# STM32F100RCT6 register map
File version: 1.0
Registers are 32-bit, access not given, reset 0x0 unless marked. A register's access mark holds for its fields unless they carry their own. Offsets are from the block's base; [hi:lo] are bit positions; {n}, {i} and the like mark numbered series; 'fields as' and 'values as' point back to an identical list.

## CEC
Base 0x40007800
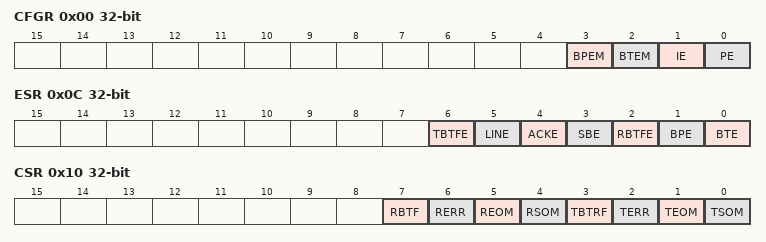
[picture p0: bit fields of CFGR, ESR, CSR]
0x00 CFGR
  [3] BPEM, [2] BTEM, [1] IE, [0] PE
0x04 OAR
  [3:0] OAR
0x08 PRE
  [13:0] PRESC
0x0C ESR
  [6] TBTFE, [5] LINE, [4] ACKE, [3] SBE, [2] RBTFE, [1] BPE, [0] BTE
0x10 CSR
  [7] RBTF, [6] RERR, [5] REOM, [4] RSOM, [3] TBTRF, [2] TERR, [1] TEOM, [0] TSOM
0x14 TXD
  [7:0] TXD
0x18 RXD
  [7:0] RXD

## AFIO
Base 0x40010000
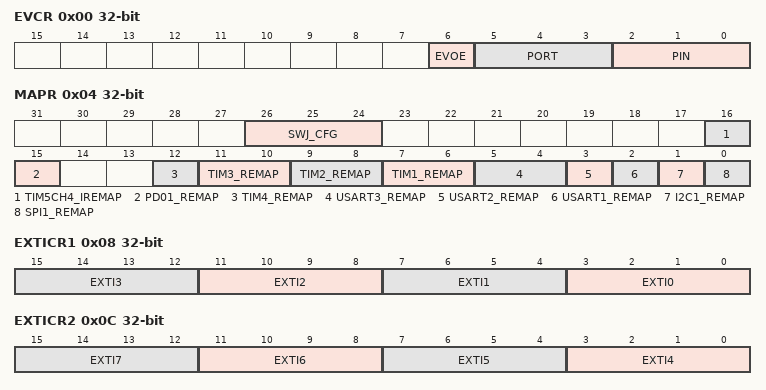
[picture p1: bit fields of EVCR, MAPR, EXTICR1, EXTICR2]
0x00 EVCR
  [6] EVOE, [5:3] PORT, [2:0] PIN
0x04 MAPR
  [26:24] SWJ_CFG, [16] TIM5CH4_IREMAP, [15] PD01_REMAP, [12] TIM4_REMAP, [11:10] TIM3_REMAP, [9:8] TIM2_REMAP, [7:6] TIM1_REMAP, [5:4] USART3_REMAP, [3] USART2_REMAP, [2] USART1_REMAP, [1] I2C1_REMAP, [0] SPI1_REMAP
0x08 EXTICR1
  [4n+3:4n] EXTI{n} (n=0..3)
0x0C EXTICR2
  [4n-13:4n-16] EXTI{n} (n=4..7)
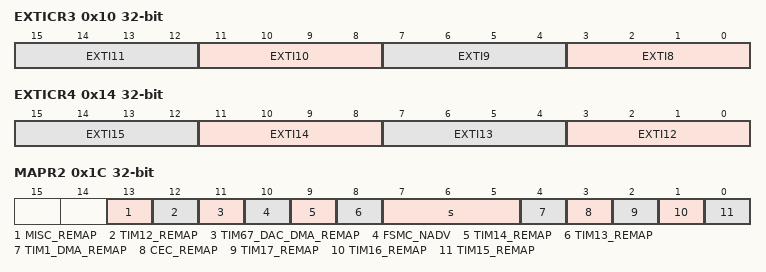
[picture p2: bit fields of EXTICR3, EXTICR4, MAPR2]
0x10 EXTICR3
  [4n-29:4n-32] EXTI{n} (n=8..11)
0x14 EXTICR4
  [4n-45:4n-48] EXTI{n} (n=12..15)
0x1C MAPR2
  [13] MISC_REMAP, [12] TIM12_REMAP, [11] TIM67_DAC_DMA_REMAP, [10] FSMC_NADV, [9] TIM14_REMAP, [8] TIM13_REMAP, [7:5] s, [4] TIM1_DMA_REMAP, [3] CEC_REMAP, [2] TIM17_REMAP, [1] TIM16_REMAP, [0] TIM15_REMAP

## EXTI
Base 0x40010400
0x00 IMR
0x04 EMR
0x08 RTSR
0x0C FTSR
0x10 SWIER
0x14 PR

## GPIOA
Base 0x40010800
Same registers: GPIOB 0x40010C00, GPIOC 0x40011000, GPIOD 0x40011400, GPIOE 0x40011800, GPIOF 0x40011C00, GPIOG 0x40012000
0x00 CRL
0x04 CRH
0x08 IDR
0x0C ODR
0x10 BSRR
0x14 BRR
0x18 LCKR

## ADC1
Base 0x40012400
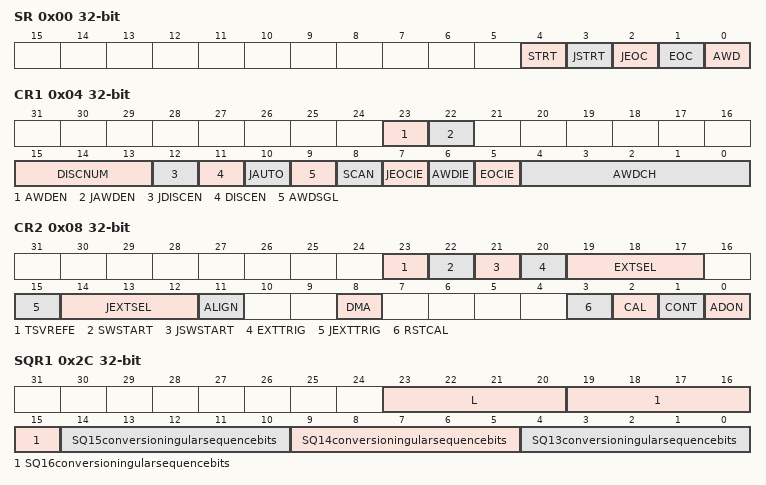
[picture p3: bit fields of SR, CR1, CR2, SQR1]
0x00 SR
  [4] STRT, [3] JSTRT, [2] JEOC, [1] EOC, [0] AWD
0x04 CR1
  [23] AWDEN, [22] JAWDEN, [15:13] DISCNUM, [12] JDISCEN, [11] DISCEN, [10] JAUTO, [9] AWDSGL, [8] SCAN, [7] JEOCIE, [6] AWDIE, [5] EOCIE, [4:0] AWDCH
0x08 CR2
  [23] TSVREFE, [22] SWSTART, [21] JSWSTART, [20] EXTTRIG, [19:17] EXTSEL, [15] JEXTTRIG, [14:12] JEXTSEL, [11] ALIGN, [8] DMA, [3] RSTCAL, [2] CAL, [1] CONT, [0] ADON
0x0C SMPR1
  [31:0] SMP
0x10 SMPR2
  [31:0] SMP
{0x10+4i} JOFR{i} (i=1..4)
  [11:0] JOFFSET{i}
0x24 HTR
  [11:0] HT
0x28 LTR
  [11:0] LT
0x2C SQR1
  [23:20] L, [5n-61:5n-65] SQ{n}conversioningularsequencebits (n=13..16)
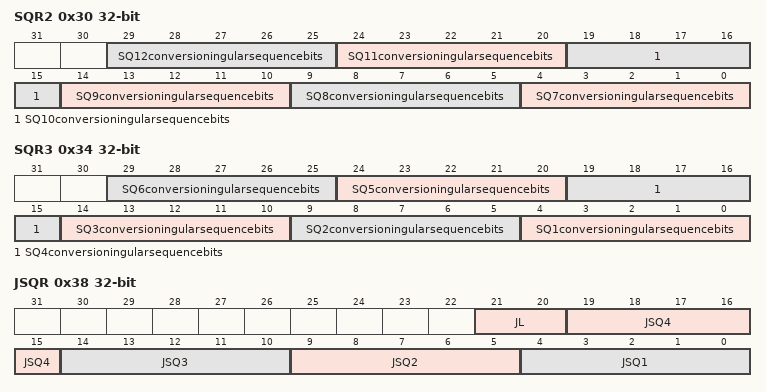
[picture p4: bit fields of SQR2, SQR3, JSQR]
0x30 SQR2
  [5n-31:5n-35] SQ{n}conversioningularsequencebits (n=7..12)
0x34 SQR3
  [5n-1:5n-5] SQ{n}conversioningularsequencebits (n=1..6)
0x38 JSQR
  [21:20] JL, [5n-1:5n-5] JSQ{n} (n=1..4)
{0x38+4i} JDR{i} (i=1..4)
  [15:0] JDATA
0x4C DR
  [15:0] gularDATA

## TIM15
Base 0x40014000
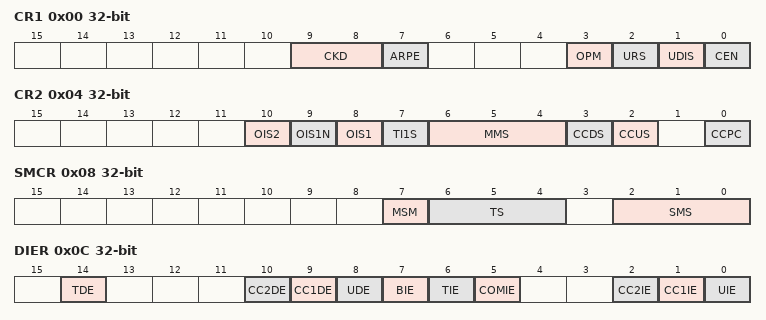
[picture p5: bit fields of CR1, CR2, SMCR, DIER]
0x00 CR1
  [9:8] CKD, [7] ARPE, [3] OPM, [2] URS, [1] UDIS, [0] CEN
0x04 CR2
  [10] OIS2, [9] OIS1N, [8] OIS1, [7] TI1S, [6:4] MMS, [3] CCDS, [2] CCUS, [0] CCPC
0x08 SMCR
  [7] MSM, [6:4] TS, [2:0] SMS
0x0C DIER
  [14] TDE, [10] CC2DE, [9] CC1DE, [8] UDE, [7] BIE, [6] TIE, [5] COMIE, [2] CC2IE, [1] CC1IE, [0] UIE
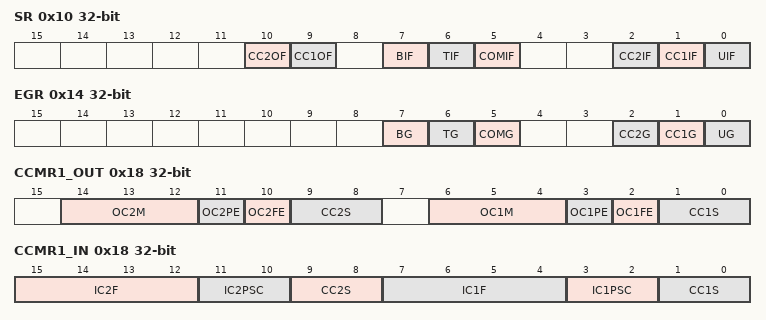
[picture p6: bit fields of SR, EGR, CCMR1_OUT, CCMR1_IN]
0x10 SR
  [10] CC2OF, [9] CC1OF, [7] BIF, [6] TIF, [5] COMIF, [2] CC2IF, [1] CC1IF, [0] UIF
0x14 EGR
  [7] BG, [6] TG, [5] COMG, [2] CC2G, [1] CC1G, [0] UG
0x18 CCMR1_OUT
  [14:12] OC2M, [11] OC2PE, [10] OC2FE, [9:8] CC2S, [6:4] OC1M, [3] OC1PE, [2] OC1FE, [1:0] CC1S
0x18 CCMR1_IN
  [15:12] IC2F, [11:10] IC2PSC, [9:8] CC2S, [7:4] IC1F, [3:2] IC1PSC, [1:0] CC1S
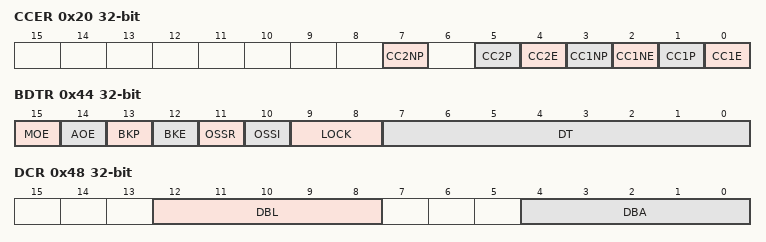
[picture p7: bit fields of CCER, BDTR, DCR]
0x20 CCER
  [7] CC2NP, [5] CC2P, [4] CC2E, [3] CC1NP, [2] CC1NE, [1] CC1P, [0] CC1E
0x24 CNT
  [15:0] CNT
0x28 PSC
  [15:0] PSC
0x2C ARR
  [15:0] ARR
0x30 RCR
  [7:0] REP
0x34 CCR1
  [15:0] CCR1
0x38 CCR2
  [15:0] CCR2
0x44 BDTR
  [15] MOE, [14] AOE, [13] BKP, [12] BKE, [11] OSSR, [10] OSSI, [9:8] LOCK, [7:0] DT
0x48 DCR
  [12:8] DBL, [4:0] DBA
0x4C DMAR
  [15:0] DMAB

## TIM16
Base 0x40014400
Same registers: TIM17 0x40014800
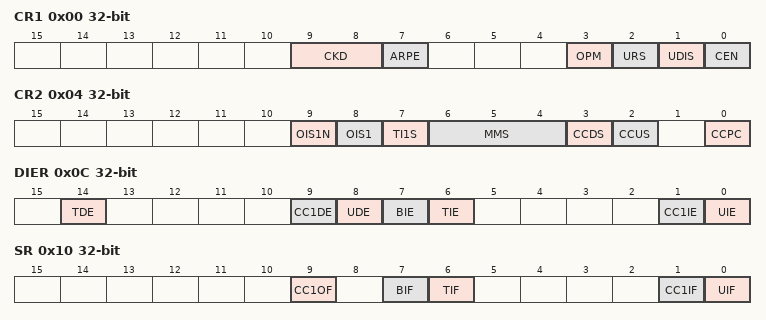
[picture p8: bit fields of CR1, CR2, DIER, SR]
0x00 CR1
  [9:8] CKD, [7] ARPE, [3] OPM, [2] URS, [1] UDIS, [0] CEN
0x04 CR2
  [9] OIS1N, [8] OIS1, [7] TI1S, [6:4] MMS, [3] CCDS, [2] CCUS, [0] CCPC
0x0C DIER
  [14] TDE, [9] CC1DE, [8] UDE, [7] BIE, [6] TIE, [1] CC1IE, [0] UIE
0x10 SR
  [9] CC1OF, [7] BIF, [6] TIF, [1] CC1IF, [0] UIF
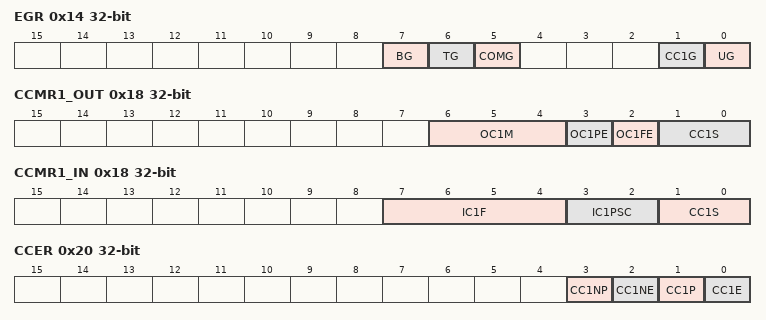
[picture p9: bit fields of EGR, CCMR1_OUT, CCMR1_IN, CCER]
0x14 EGR
  [7] BG, [6] TG, [5] COMG, [1] CC1G, [0] UG
0x18 CCMR1_OUT
  [6:4] OC1M, [3] OC1PE, [2] OC1FE, [1:0] CC1S
0x18 CCMR1_IN
  [7:4] IC1F, [3:2] IC1PSC, [1:0] CC1S
0x20 CCER
  [3] CC1NP, [2] CC1NE, [1] CC1P, [0] CC1E
0x24 CNT
  [15:0] CNT
0x28 PSC
  [15:0] PSC
0x2C ARR
  [15:0] ARR
0x30 RCR
  [7:0] REP
0x34 CCR1
  [15:0] CCR1
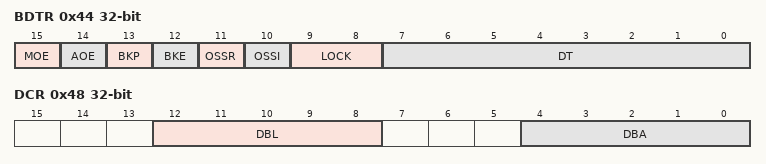
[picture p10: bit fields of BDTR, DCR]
0x44 BDTR
  [15] MOE, [14] AOE, [13] BKP, [12] BKE, [11] OSSR, [10] OSSI, [9:8] LOCK, [7:0] DT
0x48 DCR
  [12:8] DBL, [4:0] DBA
0x4C DMAR
  [15:0] DMAB

## DMA1
Base 0x40020000
Same registers: DMA2 0x40020400
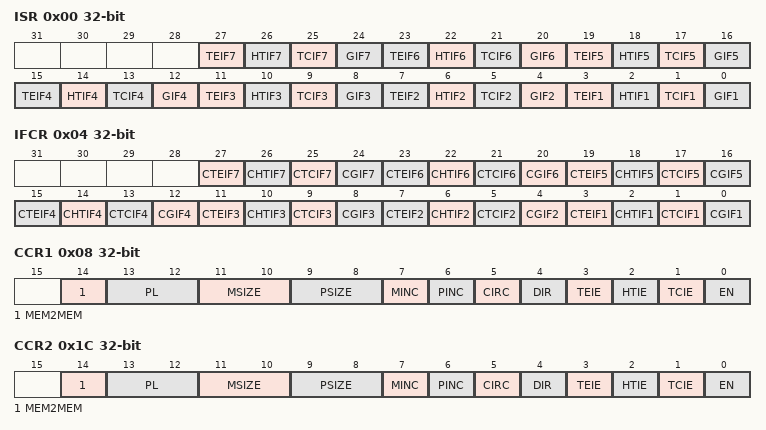
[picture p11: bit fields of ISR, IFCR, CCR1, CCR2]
0x00 ISR
  [4n-1] TEIF{n} (n=1..7), [4n-2] HTIF{n} (n=1..7), [4n-3] TCIF{n} (n=1..7), [4n-4] GIF{n} (n=1..7)
0x04 IFCR
  [4n-1] CTEIF{n} (n=1..7), [4n-2] CHTIF{n} (n=1..7), [4n-3] CTCIF{n} (n=1..7), [4n-4] CGIF{n} (n=1..7)
0x08 CCR1
  [14] MEM2MEM, [13:12] PL, [11:10] MSIZE, [9:8] PSIZE, [7] MINC, [6] PINC, [5] CIRC, [4] DIR, [3] TEIE, [2] HTIE, [1] TCIE, [0] EN
0x0C CNDTR1
  [15:0] NDT
0x10 CPAR1
  [31:0] PA
{0x0+0x14*i} CMAR{i} (i=1..7)
  [31:0] MA
0x1C CCR2
  fields as CCR1
0x20 CNDTR2
  [15:0] NDT
0x24 CPAR2
  [31:0] PA
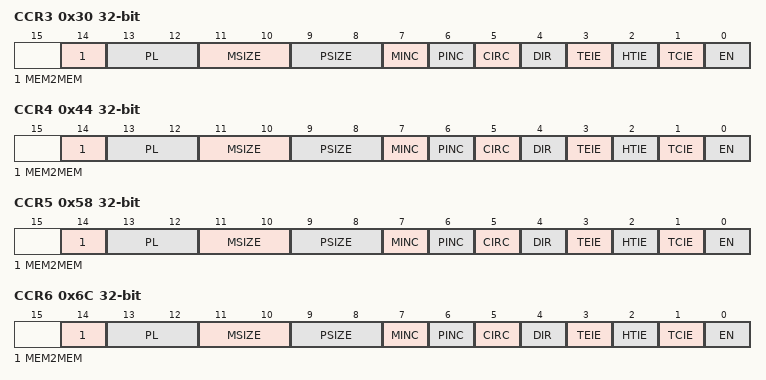
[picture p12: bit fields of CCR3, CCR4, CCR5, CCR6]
0x30 CCR3
  fields as CCR1
0x34 CNDTR3
  [15:0] NDT
0x38 CPAR3
  [31:0] PA
0x44 CCR4
  fields as CCR1
0x48 CNDTR4
  [15:0] NDT
0x4C CPAR4
  [31:0] PA
0x58 CCR5
  fields as CCR1
0x5C CNDTR5
  [15:0] NDT
0x60 CPAR5
  [31:0] PA
0x6C CCR6
  fields as CCR1
0x70 CNDTR6
  [15:0] NDT
0x74 CPAR6
  [31:0] PA
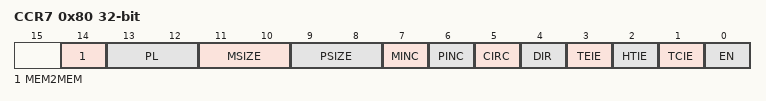
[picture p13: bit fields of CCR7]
0x80 CCR7
  fields as CCR1
0x84 CNDTR7
  [15:0] NDT
0x88 CPAR7
  [31:0] PA

## RCC
Base 0x40021000
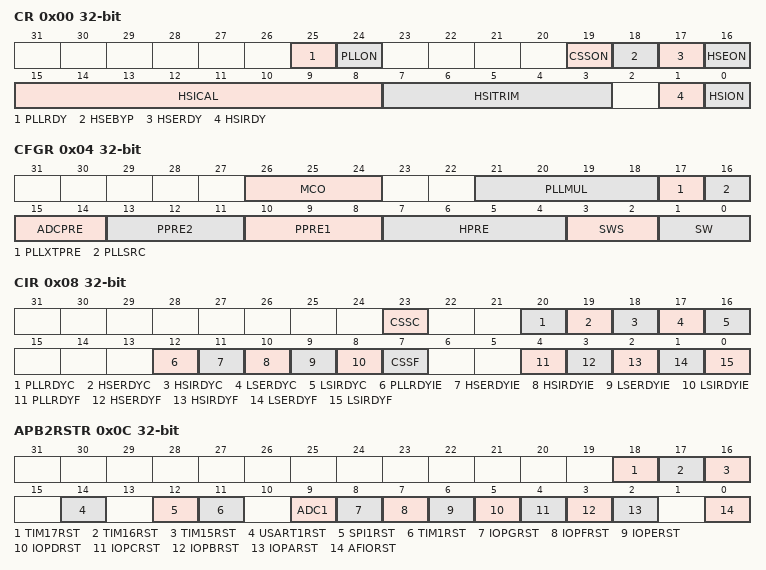
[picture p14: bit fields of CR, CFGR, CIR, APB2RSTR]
0x00 CR
  [25] PLLRDY, [24] PLLON, [19] CSSON, [18] HSEBYP, [17] HSERDY, [16] HSEON, [15:8] HSICAL, [7:3] HSITRIM, [1] HSIRDY, [0] HSION
0x04 CFGR
  [26:24] MCO, [21:18] PLLMUL, [17] PLLXTPRE, [16] PLLSRC, [15:14] ADCPRE, [13:11] PPRE2, [10:8] PPRE1, [7:4] HPRE, [3:2] SWS, [1:0] SW
0x08 CIR
  [23] CSSC, [20] PLLRDYC, [19] HSERDYC, [18] HSIRDYC, [17] LSERDYC, [16] LSIRDYC, [12] PLLRDYIE, [11] HSERDYIE, [10] HSIRDYIE, [9] LSERDYIE, [8] LSIRDYIE, [7] CSSF, [4] PLLRDYF, [3] HSERDYF, [2] HSIRDYF, [1] LSERDYF, [0] LSIRDYF
0x0C APB2RSTR
  [18] TIM17RST, [17] TIM16RST, [16] TIM15RST, [14] USART1RST, [12] SPI1RST, [11] TIM1RST, [9] ADC1, [8] IOPGRST, [7] IOPFRST, [6] IOPERST, [5] IOPDRST, [4] IOPCRST, [3] IOPBRST, [2] IOPARST, [0] AFIORST
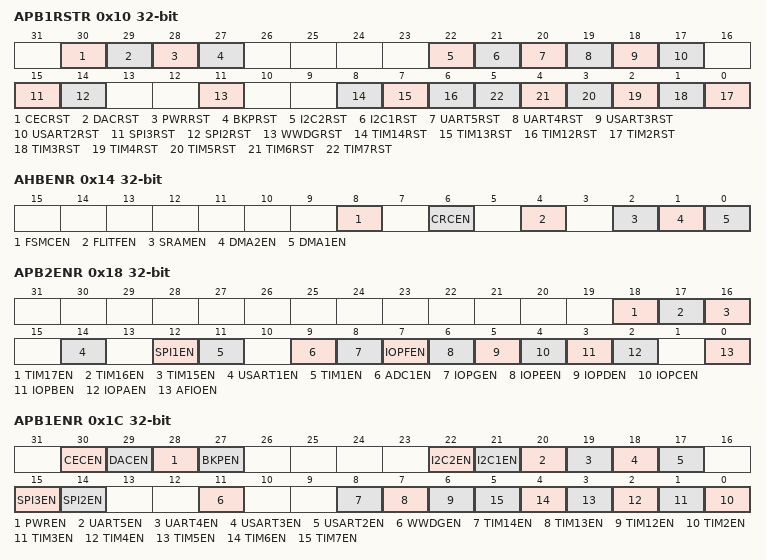
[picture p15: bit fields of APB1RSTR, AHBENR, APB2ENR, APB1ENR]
0x10 APB1RSTR
  [30] CECRST, [29] DACRST, [28] PWRRST, [27] BKPRST, [22] I2C2RST, [21] I2C1RST, [20] UART5RST, [19] UART4RST, [18] USART3RST, [17] USART2RST, [15] SPI3RST, [14] SPI2RST, [11] WWDGRST, [8] TIM14RST, [7] TIM13RST, [6] TIM12RST, [n-2] TIM{n}RST (n=2..7)
0x14 AHBENR
  [8] FSMCEN, [6] CRCEN, [4] FLITFEN, [2] SRAMEN, [1] DMA2EN, [0] DMA1EN
0x18 APB2ENR
  [18] TIM17EN, [17] TIM16EN, [16] TIM15EN, [14] USART1EN, [12] SPI1EN, [11] TIM1EN, [9] ADC1EN, [8] IOPGEN, [7] IOPFEN, [6] IOPEEN, [5] IOPDEN, [4] IOPCEN, [3] IOPBEN, [2] IOPAEN, [0] AFIOEN
0x1C APB1ENR
  [30] CECEN, [29] DACEN, [28] PWREN, [27] BKPEN, [22] I2C2EN, [21] I2C1EN, [20] UART5EN, [19] UART4EN, [18] USART3EN, [17] USART2EN, [15] SPI3EN, [14] SPI2EN, [11] WWDGEN, [8] TIM14EN, [7] TIM13EN, [6] TIM12EN, [n-2] TIM{n}EN (n=2..7)
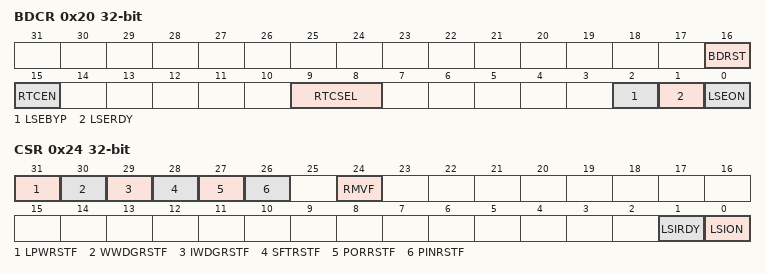
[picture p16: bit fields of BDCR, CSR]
0x20 BDCR
  [16] BDRST, [15] RTCEN, [9:8] RTCSEL, [2] LSEBYP, [1] LSERDY, [0] LSEON
0x24 CSR
  [31] LPWRSTF, [30] WWDGRSTF, [29] IWDGRSTF, [28] SFTRSTF, [27] PORRSTF, [26] PINRSTF, [24] RMVF, [1] LSIRDY, [0] LSION
0x2C CFGR2
  [3:0] PREDIV1

## CRC
Base 0x40023000
0x00 DR
  [30:0] DATA
0x04 IDR
  [7:0] DATA
0x08 CR
  [0] RESET
